# f28p65x_pctrace_regs register map
Vendor: Texas Instruments
Peripheral module from a debugger description file (folder C2000).
Address unit: 16 bits
Registers are 32-bit, read-write, no defined reset value unless marked. A register's access mark holds for its fields unless they carry their own. Offsets are as the file gives them; lines under a group give offsets from that group; [hi:lo] are bit positions; {n}, {i} and the like mark numbered series; 'fields as' and 'values as' point back to an identical list; <NAME> marks a mode.

## PCTRACE_REGS — PCTRACE Registers
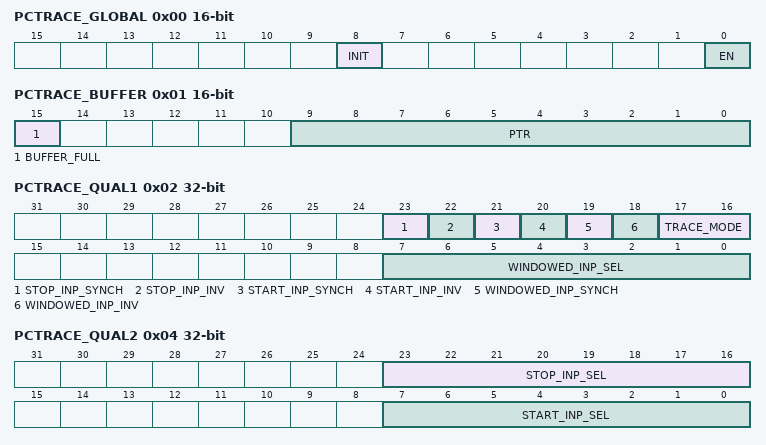
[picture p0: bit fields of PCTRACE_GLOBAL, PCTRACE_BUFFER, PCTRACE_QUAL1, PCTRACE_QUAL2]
0x00 PCTRACE_GLOBAL 16-bit
  [8] INIT — Initialize the PC Trace and buffer pointer
  [0] EN — Enable PC trace
0x01 PCTRACE_BUFFER 16-bit ro
  [15] BUFFER_FULL — Trace Buffer Full
  [9:0] PTR — Trace Buffer Pointer
0x02 PCTRACE_QUAL1
  [23] STOP_INP_SYNCH — Stop input synchronizer enable
  [22] STOP_INP_INV — Stop input Invert
  [21] START_INP_SYNCH — Start input synchronizer enable
  [20] START_INP_INV — Start input Invert
  [19] WINDOWED_INP_SYNCH — Windowed trace input synchronizer enable
  [18] WINDOWED_INP_INV — Windowed trace Input Invert
  [17:16] TRACE_MODE — Trace qualifier mode
  [7:0] WINDOWED_INP_SEL — Windowed trace qualifier
0x04 PCTRACE_QUAL2
  [23:16] STOP_INP_SEL — Trace Stop event select
  [7:0] START_INP_SEL — Trace Start event select
0x06 PCTRACE_LOGPC_SOFTENABLE ro
  [21:0] PC_SOFTENABLE — PC when PC Trace was last enabled by software
0x08 PCTRACE_LOGPC_SOFTDISABLE ro
  [21:0] PC_SOFTDISABLE — PC when PC Trace was last disabled by software
